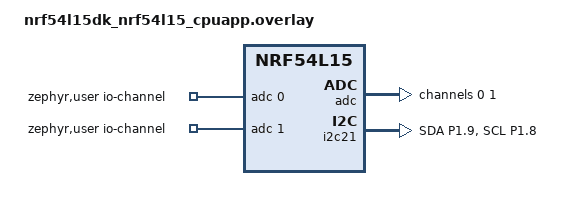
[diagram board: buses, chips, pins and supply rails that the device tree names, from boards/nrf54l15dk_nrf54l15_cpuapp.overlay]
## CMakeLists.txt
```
cmake_minimum_required(VERSION 3.20.0)

find_package(Zephyr REQUIRED HINTS $ENV{ZEPHYR_BASE})
project(npm2100_nrf54l15_BFG)

zephyr_include_directories(src/common src/ble src/pmic src/adc) # (inc .)

# NORDIC SDK APP START
target_sources(app PRIVATE
	src/main.c
	src/adc/npm_adc.c
	src/ble/ble_periph_pmic.c
	src/pmic/pmic.c
)
```

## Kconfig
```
#
# Copyright (c) 2025 Nordic Semiconductor
#
# SPDX-License-Identifier: LicenseRef-Nordic-5-Clause
#

menu "Zephyr"
source "Kconfig.zephyr"
endmenu

menu "Sample configuration"

choice BATTERY_MODEL
	prompt "Initial battery model"
	default BATTERY_MODEL_ALKALINE_AA
	help
	  Select the initial battery model to use.
	  The battery model can be changed at runtime using shell commands.

config BATTERY_MODEL_ALKALINE_AA
	bool "Alkaline AA"
	help
	  Alkaline AA cylindrical battery.

config BATTERY_MODEL_ALKALINE_AAA
	bool "Alkaline AAA"
	help
	  Alkaline AAA cylindrical battery.

config BATTERY_MODEL_ALKALINE_2SAA
	bool "Alkaline 2SAA"
	help
	  Two Alkaline AA cylindrical batteries in series.

config BATTERY_MODEL_ALKALINE_2SAAA
	bool "Alkaline 2SAAA"
	help
	  Two Alkaline AAA cylindrical batteries in series.

config BATTERY_MODEL_ALKALINE_LR44
	bool "Alkaline LR44"
	help
	  Alkaline LR44 coin cell battery.

config BATTERY_MODEL_LITHIUM_CR2032
	bool "Lithium CR2032"
	help
	  Lithium-manganese dioxide CR2032 coin cell battery.

endchoice

endmenu
```

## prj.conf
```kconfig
# Button and LED library
CONFIG_DK_LIBRARY=y

# Bluetooth LE
CONFIG_BT=y
CONFIG_BT_PERIPHERAL=y
CONFIG_BT_DEVICE_NAME="npm2100_nrf54l15_BFG"
CONFIG_BT_MAX_CONN=1
# CONFIG_BT_BUF_ACL_TX_COUNT=10 

CONFIG_BT_NSMS=y
CONFIG_BT_BAS=y

# add DLE for the rd all characteristic data to not be fragmented
CONFIG_BT_GATT_CLIENT=y
CONFIG_BT_USER_PHY_UPDATE=y
CONFIG_BT_CTLR_PHY_CODED=y
CONFIG_BT_USER_DATA_LEN_UPDATE=y
CONFIG_BT_CTLR_DATA_LENGTH_MAX=124
CONFIG_BT_BUF_ACL_TX_SIZE=124
CONFIG_BT_BUF_ACL_RX_SIZE=124
CONFIG_BT_L2CAP_TX_MTU=120

# Increase stack size for the main thread and System Workqueue
CONFIG_SYSTEM_WORKQUEUE_STACK_SIZE=2048
CONFIG_MAIN_STACK_SIZE=2048

# !DBG 
#I2C
CONFIG_I2C=y
CONFIG_CBPRINTF_FP_SUPPORT=y


# Power savings if you disable these.
CONFIG_LOG=y
CONFIG_SERIAL=y
CONFIG_LOG_MODE_DEFERRED=y
#CONFIG_LOG_DEFAULT_LEVEL=0

CONFIG_SYSTEM_WORKQUEUE_STACK_SIZE=4096
CONFIG_HEAP_MEM_POOL_SIZE=4096

# Event manager
# CONFIG_APP_EVENT_MANAGER=y
# CONFIG_APP_EVENT_MANAGER_LOG_LEVEL_OFF=y
# CONFIG_CAF=y
# CONFIG_CAF_LEDS=y
# CONFIG_CAF_LEDS_PWM=y

# tx power config examples. not all socs support all +/-, check your soc
# CONFIG_BT_CTRL_TX_PWR_PLUS_8=y
# CONFIG_BT_CTLR_TX_PWR_0=y
# CONFIG_BT_CTLR_TX_PWR_MINUS_40=y

CONFIG_PM_DEVICE=y
CONFIG_PM_DEVICE_RUNTIME=y

# from FG
# CONFIG_SHELL=y
# CONFIG_LOG=y
# CONFIG_LOG_CMDS=y
# CONFIG_I2C_SHELL=y

# !DBG NOT AA anymore. testing if i want it here or in app.
# instead of using shell to pick model, we default to AA.
# CONFIG_BATTERY_MODEL_ALKALINE_AA=y

CONFIG_GPIO=y
CONFIG_REGULATOR=y
CONFIG_SENSOR=y
CONFIG_NRF_FUEL_GAUGE=y
CONFIG_NRF_FUEL_GAUGE_VARIANT_PRIMARY_CELL=y
CONFIG_REQUIRES_FLOAT_PRINTF=y


# Add ADC support
CONFIG_ADC=y
```

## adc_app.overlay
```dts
/*
 * SPDX-License-Identifier: Apache-2.0
 * auth: ddhd
 *
 * Copyright (c) 2026 Nordic Semiconductor ASA
 */
/ {
	zephyr,user {
		io-channels = <&adc 0>, <&adc 1>;
	};
};

&adc {
	#address-cells = <1>;
	#size-cells = <0>;
	status = "okay";
	channel@0 {
		reg = <0>;
		zephyr,gain = "ADC_GAIN_1_4";
		zephyr,reference = "ADC_REF_INTERNAL";
		zephyr,acquisition-time = <ADC_ACQ_TIME_DEFAULT>;
		zephyr,input-positive = <NRF_SAADC_AIN0>; /* P1.04 on seeed board */
		zephyr,resolution = <14>;
	};
	channel@1 {
		reg = <1>;
		zephyr,gain = "ADC_GAIN_1_4";
		zephyr,reference = "ADC_REF_INTERNAL";
		zephyr,acquisition-time = <ADC_ACQ_TIME_DEFAULT>;
		zephyr,input-positive = <NRF_SAADC_AIN1>; /* P1.05 on the seeed board */
		zephyr,resolution = <14>;
	};
};
```

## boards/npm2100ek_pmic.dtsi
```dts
/*
 * Copyright (c) 2025 Nordic Semiconductor ASA
 *
 * SPDX-License-Identifier: LicenseRef-Nordic-5-Clause
 */

#include <dt-bindings/regulator/npm2100.h>

npm2100ek_pmic: pmic@74 {
	compatible = "nordic,npm2100";
	reg = <0x74>;

	npm2100ek_gpio: gpio-controller {
		compatible = "nordic,npm2100-gpio";
		gpio-controller;
		#gpio-cells = <2>;
		ngpios = <2>;
	};

	npm2100ek_regulators: regulators {
		compatible = "nordic,npm2100-regulator";

		/* limits are set to min/max allowed values */
		npm2100ek_boost: BOOST {
			regulator-min-microvolt = <1800000>;
			regulator-max-microvolt = <3300000>;
			regulator-init-microamp = <0>;
		};

		npm2100ek_ldosw: LDOSW {
			regulator-min-microvolt = <800000>;
			regulator-max-microvolt = <3000000>;
		};
	};

	npm2100ek_wdt: watchdog {
		compatible = "nordic,npm2100-wdt";
	};

	npm2100ek_vbat: vbat {
		compatible = "nordic,npm2100-vbat";
	};
};
```

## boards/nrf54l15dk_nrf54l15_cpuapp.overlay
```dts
/*
 * SPDX-License-Identifier: Apache-2.0
 *
 * Copyright (c) 2025 Nordic Semiconductor ASA
 */
/ {
	zephyr,user {
		io-channels = <&adc 0>, <&adc 1>;
	};
};

&adc {
	#address-cells = <1>;
	#size-cells = <0>;
	status = "okay";
	channel@0 {
		reg = <0>;
		zephyr,gain = "ADC_GAIN_1_4";
		zephyr,reference = "ADC_REF_INTERNAL";
		zephyr,acquisition-time = <ADC_ACQ_TIME_DEFAULT>;
		zephyr,input-positive = <NRF_SAADC_AIN4>; /* P1.11 for the nRF54L15 DK, BOOST/VOUT on pmic */
		zephyr,resolution = <14>;
	};
	channel@1 {
		reg = <1>;
		zephyr,gain = "ADC_GAIN_1_4";
		zephyr,reference = "ADC_REF_INTERNAL";
		zephyr,acquisition-time = <ADC_ACQ_TIME_DEFAULT>;
		zephyr,input-positive = <NRF_SAADC_AIN5>; /* Example: P1.12 for the nRF54L15 DK, LSLDO OUT on pmic */
		zephyr,resolution = <14>;
	};
};

&pinctrl {
	i2c21_default_alt: i2c21_default_alt {
		group1 {
			psels = <NRF_PSEL(TWIM_SDA, 1, 9)>,
					<NRF_PSEL(TWIM_SCL, 1, 8)>;
			bias-pull-up;
		};
	};

	i2c21_sleep_alt: i2c21_sleep_alt {
		group1 {
			psels = <NRF_PSEL(TWIM_SDA, 1, 9)>,
					<NRF_PSEL(TWIM_SCL, 1, 8)>;
			low-power-enable;
		};
	};
};

&i2c21 {
	status = "okay";
	pinctrl-0 = <&i2c21_default_alt>;
	pinctrl-1 = <&i2c21_sleep_alt>;
	pinctrl-names = "default", "sleep";

	#include "npm2100ek_pmic.dtsi"
};
```

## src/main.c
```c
/*
 * npm2100_nrf54l15_BFG
 * main.c
 * Bluetooth fuel gauge demo application main file
 * auth: ddhd
 * SPDX-License-Identifier: LicenseRef-Nordic-5-Clause
 */

#include <dk_buttons_and_leds.h>
#include <zephyr/device.h>
#include <zephyr/devicetree.h>
#include <zephyr/kernel.h>

#include <zephyr/logging/log.h>

#include "threads.h"
#include "tsync.h"

LOG_MODULE_REGISTER(main, LOG_LEVEL_INF);

#define DK_STATUS_LED DK_LED1
K_SEM_DEFINE(sem_gpio_ready, 0, 1);

int main(void)
{
    int err;

    k_sem_take(&sem_pmic_ready, K_FOREVER);
    k_sem_give(&sem_gpio_ready);
    k_sem_take(&sem_ble_ready, K_FOREVER);

    for (;;)
    {
        k_sleep(K_MSEC(2000));
    }
    return err;
}
```
